# R7FA6M3AH register map
Vendor: Renesas; Series: RA6; File version: 1.2
CPU: CM4 r0p1, little endian, MPU, FPU, VTOR, 4 interrupt priority bits
Registers are 32-bit, read-write, reset 0x0 unless marked. A register's access mark holds for its fields unless they carry their own. Offsets are from the block's base; [hi:lo] are bit positions.

## DMA — DMAC Module Activation
Base 0x40005200
0x00 DMAST 8-bit — DMA Module Activation Register
  [0] DMST — DMAC Operation Enable
    0=DMAC activation is disabled; 1=DMAC activation is enabled

## DTC — Data Transfer Controller
Base 0x40005400
0x00 DTCCR 8-bit reset 0x8 — DTC Control Register
  [4] RRS — DTC Transfer Information Read Skip Enable.
    0=Do not skip transfer information read; 1=Skip transfer information read when vector numbers match
0x04 DTCVBR — DTC Vector Base Register
  [31:0] DTCVBR — DTC Vector Base Address.Note: A value cannot be set in the lower-order 10 bits. These bits are fixed to 0.
0x0C DTCST 8-bit — DTC Module Start Register
  [0] DTCST — DTC Module Start
    0=DTC module stop; 1=DTC module start
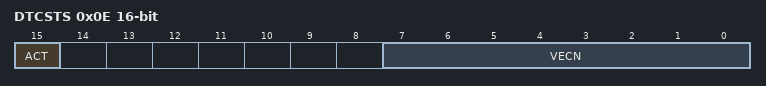
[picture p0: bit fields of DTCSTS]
0x0E DTCSTS 16-bit ro — DTC Status Register
  [15] ACT — DTC Active Flag
    0=DTC transfer operation is not in progress; 1=DTC transfer operation is in progress
  [7:0] VECN — DTC-Activating Vector Number MonitoringThese bits indicate the vector number for the activating source when DTC transfer is in progress.The value is only valid if DTC transfer is in progress (the value of the ACT flag is 1)

## DBG — Debug Function
Base 0x4001B000
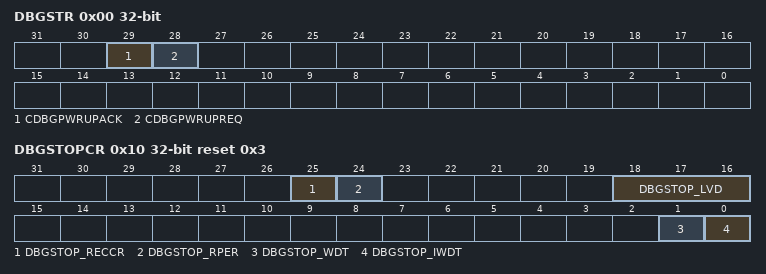
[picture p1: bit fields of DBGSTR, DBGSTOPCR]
0x00 DBGSTR ro — Debug Status Register
  [29] CDBGPWRUPACK — Debug power-up acknowledge
    0=Debug power-up request is not acknowledged; 1=Debug power-up request is acknowledged
  [28] CDBGPWRUPREQ — Debug power-up request
    0=OCD is not requesting debug power-up; 1=OCD is requesting debug power-up
0x10 DBGSTOPCR reset 0x3 — Debug Stop Control Register
  [25] DBGSTOP_RECCR — Mask bit for RAM ECC error reset/interrupt
    0=Enable RAM ECC error reset/interrupt; 1=Mask RAM ECC error reset/interrupt
  [24] DBGSTOP_RPER — Mask bit for RAM parity error reset/interrupt
    0=Enable RAM parity error reset/interrupt; 1=Mask RAM parity error reset/interrupt
  [18:16] DBGSTOP_LVD — b18: Mask bit for LVD2 reset/interrupt (0:enable / 1:Mask)b17: Mask bit for LVD1 reset/interrupt (0:enable / 1:Mask)b16: Mask bit for LVD0 reset (0:enable / 1:Mask)
  [1] DBGSTOP_WDT — Mask bit for WDT reset/interrupt
    0=Mask WDT reset/interrupt; 1=Enable WDT reset
  [0] DBGSTOP_IWDT — Mask bit for IWDT reset/interrupt
    0=Mask IWDT reset/interrupt; 1=Enable IWDT reset
0x20 TRACECTR — Trace Control Register
  [31] ENETBFULL — Enable bit for halt request by ETB full
    0=ETB full does not cause CPU halt; 1=ETB full cause CPU halt

## TSN — Temperature Sensor
Base 0x4005D000
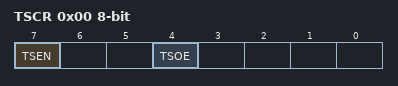
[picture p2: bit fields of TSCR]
0x00 TSCR 8-bit — Temperature Sensor Control Register
  [7] TSEN — Temperature Sensor Output Enable
    0=Stops the temperature sensor; 1=Starts the temperature sensor
  [4] TSOE — Temperature Sensor Enable
    0=Disables output from the temperature sensor to the 12-bit A/D converter; 1=Enables output from the temperature sensor to the 12-bit A/D converter

## ACMPHS0 — High-Speed Analog Comparator 0
Base 0x40085000
Same registers: ACMPHS1 0x40085100, ACMPHS2 0x40085200, ACMPHS3 0x40085300, ACMPHS4 0x40085400, ACMPHS5 0x40085500
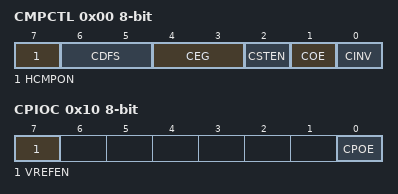
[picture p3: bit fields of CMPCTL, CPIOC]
0x00 CMPCTL 8-bit — Comparator Control Register
  [7] HCMPON — Comparator operation control
    0=Operation stopped (the comparator outputs a low-level signal); 1=Operation enabled (input to the comparator pins is enabled
  [6:5] CDFS — Noise filter selection
    0=Noise filter not used; 1=Noise filter sampling frequency is 2^3/PCLKB; 2=Noise filter sampling frequency is 2^4/PCLKB; 3=Noise filter sampling frequency is 2^5/PCLKB
  [4:3] CEG — Selection of valid edge (Edge selector)
    0=No edge selection; 1=Rising edge selection; 2=Falling edge selection; 3=Both-edge selection
  [2] CSTEN — Interrupt Select
    0=Output via the Edge selector; 1=Direct output
  [1] COE — Comparator output enable
    0=Comparator output disabled (the output signal is low level); 1=Comparator output enabled
  [0] CINV — Comparator output polarity selection
    0=Comparator output not inverted; 1=Comparator output inverted
0x04 CMPSEL0 8-bit — Comparator Input Select Register
  [3:0] CMPSEL — Comparator input selection
    0=No input; 1=IVCMP0 selected; 2=IVCMP1 selected; 4=IVCMP2 selected; 8=IVCMP3 selected; other=others (Setting prohibited)
0x08 CMPSEL1 8-bit — Comparator Reference Voltage Select Register
  [3:0] CRVS — Reference voltage selection
    0=No reference voltage; 1=IVREF0 selected; 2=IVREF1 selected; 4=IVREF2 selected; 8=IVREF3 selected; other=others (Setting prohibited)
0x0C CMPMON 8-bit ro — Comparator Output Monitor Register
  [0] CMPMON — Comparator output monitor
    0=Comparator output Low; 1=Comparator output High
0x10 CPIOC 8-bit — Comparator Output Control Register
  [7] VREFEN — Internal Vref enable
    0=Internal Vref disable; 1=Internal Vref enable
  [0] CPOE — Comparator output selection
    0=VCOUT pin output of the comparator is disabled (the output signal is low level); 1=VCOUT pin output of the comparator is enabled
